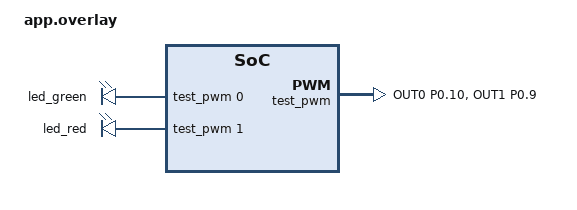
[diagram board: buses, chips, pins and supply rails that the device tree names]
/* SPDX-License-Identifier: MIT */

#include <zephyr/dt-bindings/pinctrl/nrf-pinctrl.h>
#include <zephyr/dt-bindings/pwm/pwm.h>

/ {
    test {
        #address-cells = <1>;
        #size-cells = <1>;

        test_pwm: pwm@0 {
            compatible = "dygma,loader-test-pwm";
            reg = <0x0 0x1000>;
            #pwm-cells = <3>;
            pinctrl-0 = <&test_led_default>;
            pinctrl-names = "default";
            status = "okay";
        };
    };

    test_pinctrl {
        compatible = "nordic,nrf-pinctrl";

        test_led_default: test_led_default {
            group1 {
                psels = <NRF_PSEL(PWM_OUT0, 0, 10)>, <NRF_PSEL(PWM_OUT1, 0, 9)>;
            };
        };
    };

    status-leds {
        compatible = "pwm-leds";
        led_green: green {
            pwms = <&test_pwm 0 PWM_USEC(100) PWM_POLARITY_NORMAL>;
        };
        led_red: red {
            pwms = <&test_pwm 1 PWM_USEC(100) PWM_POLARITY_NORMAL>;
        };
    };
};
